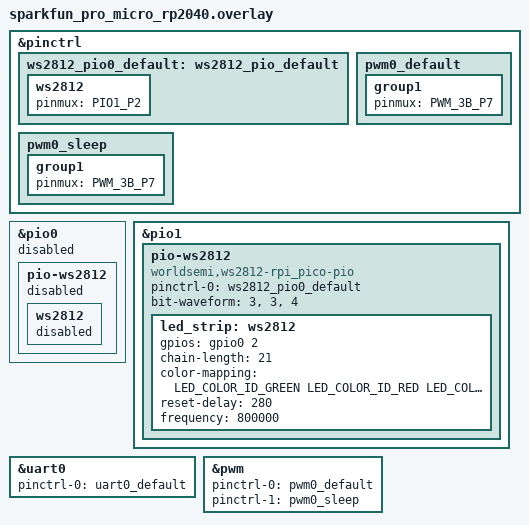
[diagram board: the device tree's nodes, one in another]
#include <dt-bindings/led/led.h>
#include <dt-bindings/pinctrl/rpi-pico-rp2040-pinctrl.h>
#include <zephyr/dt-bindings/pwm/pwm.h>
#include <zephyr/dt-bindings/led/led.h>
&pinctrl {

    ws2812_pio0_default: ws2812_pio_default  {
		ws2812 {
            pinmux = <PIO1_P2>;
		};
	};
    pwm0_default: pwm0_default {
        group1 {
            pinmux = <PWM_3B_P7>;
        };
    };
    pwm0_sleep: pwm0_sleep {
        group1 {
            pinmux = <PWM_3B_P7>;
        };
    };
};
&pio0 {
    status = "disabled";
    pio-ws2812 {
        status = "disabled";

        ws2812: ws2812 {
            status = "disabled";
        };
    };
};

&pio1 {
    status = "okay";

    pio-ws2812 {
		compatible = "worldsemi,ws2812-rpi_pico-pio";
		status = "okay";
		pinctrl-0 = <&ws2812_pio0_default>;
		pinctrl-names = "default";
		bit-waveform = <3>, <3>, <4>;

		led_strip: ws2812 {
			status = "okay";
			gpios = <&gpio0 2 GPIO_ACTIVE_HIGH>;
			chain-length = <21>;
			color-mapping = <LED_COLOR_ID_GREEN
					 LED_COLOR_ID_RED
					 LED_COLOR_ID_BLUE>;
			reset-delay = <280>;
			frequency = <800000>;
		};
	};
};


&uart0 {
    status = "okay";
    pinctrl-0 = <&uart0_default>;
    pinctrl-names = "default";
};

&pwm {
    status = "okay";
    pinctrl-0 = <&pwm0_default>;
    pinctrl-1 = <&pwm0_sleep>;
    pinctrl-names = "default", "sleep";
};
